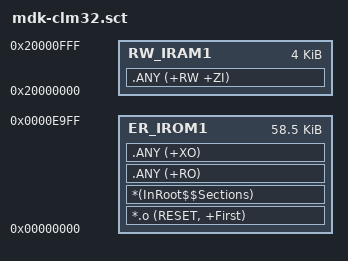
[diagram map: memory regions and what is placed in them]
; *************************************************************
; *** Scatter-Loading Description File generated by uVision ***
; *************************************************************

; LR_IROM1 0x08000000 0xD600  {    ; load region size_region
;   ER_IROM1 0x08000000 0xD600  {  ; load address = execution address
;    *.o (RESET, +First)
;    *(InRoot$$Sections)
;    .ANY (+RO)
;    .ANY (+XO)
;   }
; 
;   RW_IRAM1 0x20000000 0x00004000  {  ; RW data
;    .ANY (+RW +ZI)
;   }
; }


LR_IROM1 0x00000000 0xEA00  {    ; load region size_region
  ER_IROM1 0x00000000 0xEA00  {  ; load address = execution address
   *.o (RESET, +First)
   *(InRoot$$Sections)
   .ANY (+RO)
   .ANY (+XO)
  }

  RW_IRAM1 0x20000000 0x00001000  {  ; RW data
   .ANY (+RW +ZI)
  }
}

